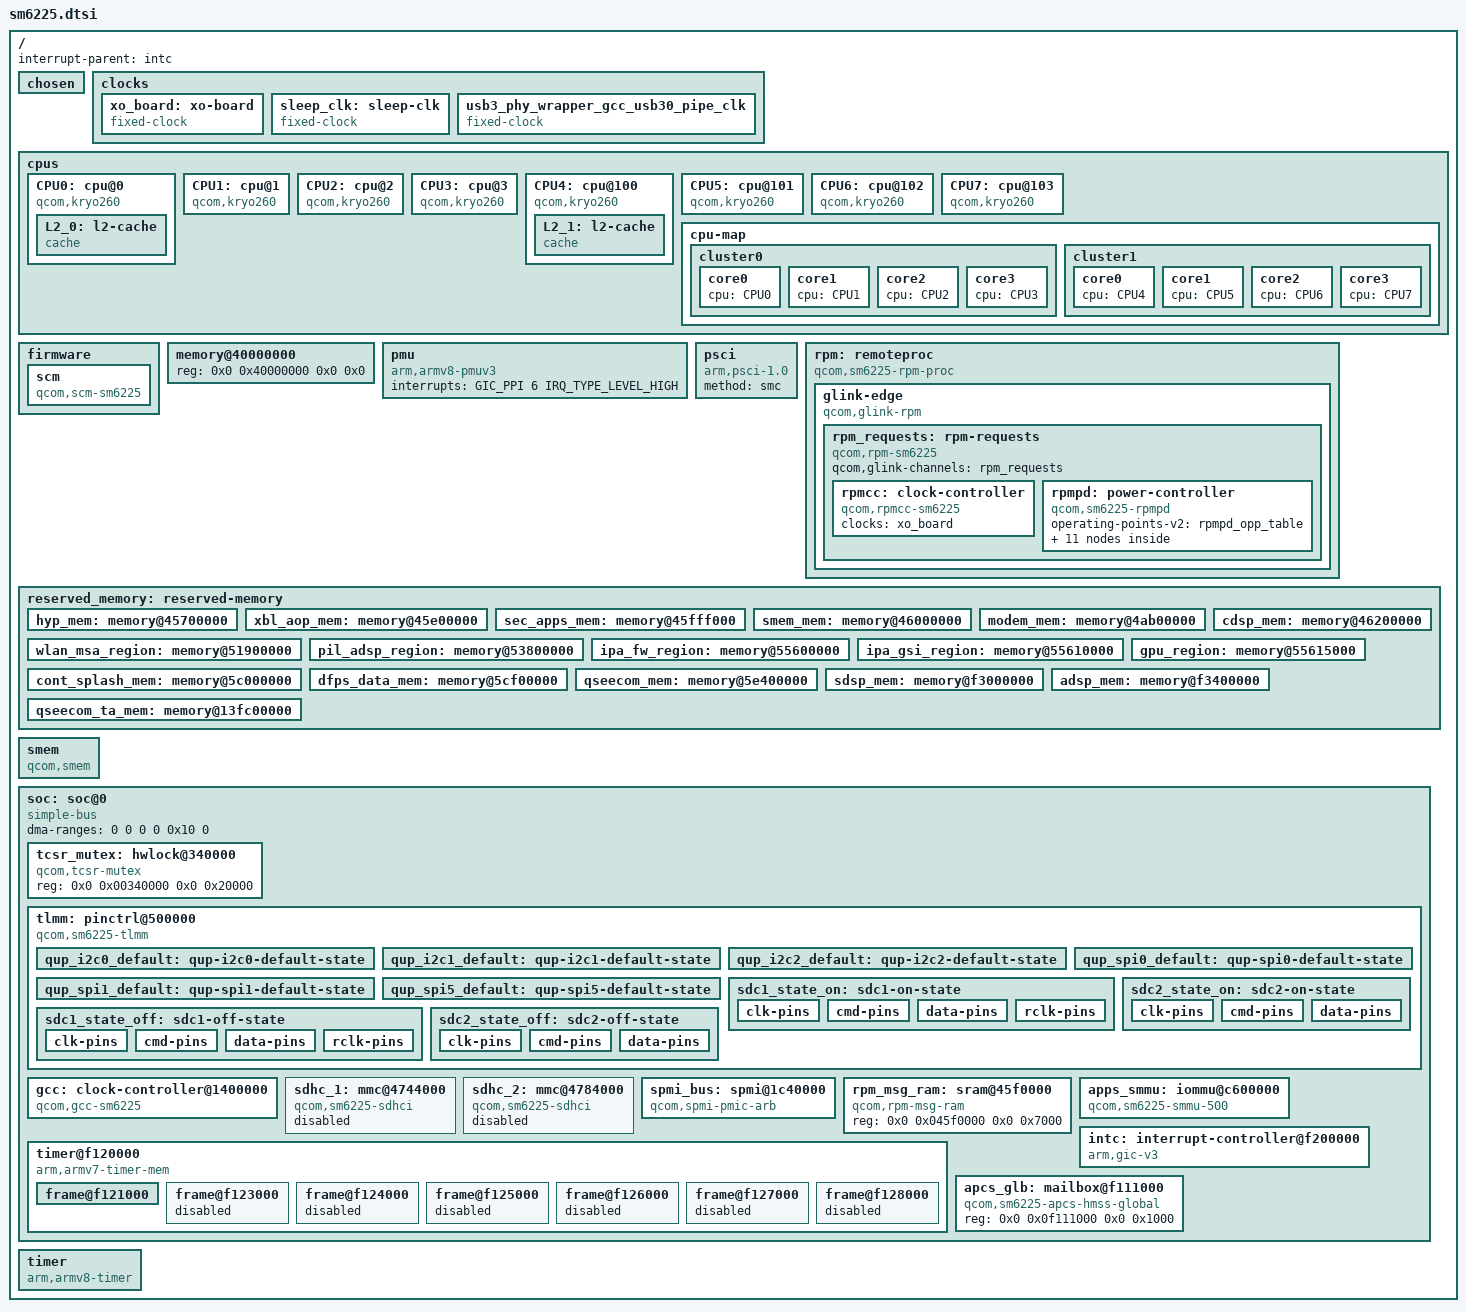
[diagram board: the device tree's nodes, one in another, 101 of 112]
// SPDX-License-Identifier: BSD-3-Clause
/*
 * Copyright (c) 2021, Martin Botka <martin.botka@somainline.org>
 */

#include <dt-bindings/clock/qcom,gcc-sm6225.h>
#include <dt-bindings/clock/qcom,rpmcc.h>
#include <dt-bindings/dma/qcom-gpi.h>
#include <dt-bindings/firmware/qcom,scm.h>
#include <dt-bindings/gpio/gpio.h>
#include <dt-bindings/interconnect/qcom,sm6115.h>
#include <dt-bindings/interconnect/qcom,rpm-icc.h>
#include <dt-bindings/interrupt-controller/arm-gic.h>
#include <dt-bindings/power/qcom-rpmpd.h>
#include <dt-bindings/thermal/thermal.h>

/ {
	interrupt-parent = <&intc>;
	#address-cells = <2>;
	#size-cells = <2>;

	chosen { };

	clocks {
		xo_board: xo-board {
			compatible = "fixed-clock";
			#clock-cells = <0>;
			clock-frequency = <19200000>;
			clock-output-names = "xo_board";
		};

		sleep_clk: sleep-clk {
			compatible = "fixed-clock";
			#clock-cells = <0>;
			clock-frequency = <32764>;
			clock-output-names = "sleep_clk";
		};

		usb3_phy_wrapper_gcc_usb30_pipe_clk: usb3_phy_wrapper_gcc_usb30_pipe_clk {
			compatible = "fixed-clock";
			#clock-cells = <0>;
			clock-frequency = <1000>;
			clock-output-names = "usb3_phy_wrapper_gcc_usb30_pipe_clk";
		};
	};

	cpus {
		#address-cells = <2>;
		#size-cells = <0>;

		CPU0: cpu@0 {
			device_type = "cpu";
			compatible = "qcom,kryo260";
			reg = <0x0 0x0>;
			enable-method = "psci";
			capacity-dmips-mhz = <1024>;
			next-level-cache = <&L2_0>;
			L2_0: l2-cache {
				compatible = "cache";
			};
		};

		CPU1: cpu@1 {
			device_type = "cpu";
			compatible = "qcom,kryo260";
			reg = <0x0 0x1>;
			enable-method = "psci";
			capacity-dmips-mhz = <1024>;
			next-level-cache = <&L2_0>;
		};

		CPU2: cpu@2 {
			device_type = "cpu";
			compatible = "qcom,kryo260";
			reg = <0x0 0x2>;
			enable-method = "psci";
			capacity-dmips-mhz = <1024>;
			next-level-cache = <&L2_0>;
		};

		CPU3: cpu@3 {
			device_type = "cpu";
			compatible = "qcom,kryo260";
			reg = <0x0 0x3>;
			enable-method = "psci";
			capacity-dmips-mhz = <1024>;
			next-level-cache = <&L2_0>;
		};

		CPU4: cpu@100 {
			device_type = "cpu";
			compatible = "qcom,kryo260";
			reg = <0x0 0x100>;
			enable-method = "psci";
			capacity-dmips-mhz = <1638>;
			next-level-cache = <&L2_1>;
			L2_1: l2-cache {
				compatible = "cache";
			};
		};

		CPU5: cpu@101 {
			device_type = "cpu";
			compatible = "qcom,kryo260";
			reg = <0x0 0x101>;
			enable-method = "psci";
			capacity-dmips-mhz = <1638>;
			next-level-cache = <&L2_1>;
		};

		CPU6: cpu@102 {
			device_type = "cpu";
			compatible = "qcom,kryo260";
			reg = <0x0 0x102>;
			enable-method = "psci";
			capacity-dmips-mhz = <1638>;
			next-level-cache = <&L2_1>;
		};

		CPU7: cpu@103 {
			device_type = "cpu";
			compatible = "qcom,kryo260";
			reg = <0x0 0x103>;
			enable-method = "psci";
			capacity-dmips-mhz = <1638>;
			next-level-cache = <&L2_1>;
		};

		cpu-map {
			cluster0 {
				core0 {
					cpu = <&CPU0>;
				};

				core1 {
					cpu = <&CPU1>;
				};

				core2 {
					cpu = <&CPU2>;
				};

				core3 {
					cpu = <&CPU3>;
				};
			};

			cluster1 {
				core0 {
					cpu = <&CPU4>;
				};

				core1 {
					cpu = <&CPU5>;
				};

				core2 {
					cpu = <&CPU6>;
				};

				core3 {
					cpu = <&CPU7>;
				};
			};
		};
	};

	firmware {
		scm: scm {
			compatible = "qcom,scm-sm6225", "qcom,scm";
			#reset-cells = <1>;
		};
	};

	memory@40000000 {
		/* We expect the bootloader to fill in the size */
		reg = <0x0 0x40000000 0x0 0x0>;
		device_type = "memory";
	};

	pmu {
		compatible = "arm,armv8-pmuv3";
		interrupts = <GIC_PPI 6 IRQ_TYPE_LEVEL_HIGH>;
	};

	psci {
		compatible = "arm,psci-1.0";
		method = "smc";
	};

	rpm: remoteproc {
		compatible = "qcom,sm6225-rpm-proc", "qcom,rpm-proc";

		glink-edge {
			compatible = "qcom,glink-rpm";

			interrupts = <GIC_SPI 194 IRQ_TYPE_EDGE_RISING>;
			qcom,rpm-msg-ram = <&rpm_msg_ram>;
			mboxes = <&apcs_glb 0>;

			rpm_requests: rpm-requests {
				compatible = "qcom,rpm-sm6225";
				qcom,glink-channels = "rpm_requests";

				rpmcc: clock-controller {
					compatible = "qcom,rpmcc-sm6225", "qcom,rpmcc";
					#clock-cells = <1>;
					clocks = <&xo_board>;
					clock-names = "xo";
				};

				rpmpd: power-controller {
					compatible = "qcom,sm6225-rpmpd";
					#power-domain-cells = <1>;
					operating-points-v2 = <&rpmpd_opp_table>;

					rpmpd_opp_table: opp-table {
						compatible = "operating-points-v2";

						rpmpd_opp_ret: opp1 {
							opp-level = <RPM_SMD_LEVEL_RETENTION>;
						};

						rpmpd_opp_ret_plus: opp2 {
							opp-level = <RPM_SMD_LEVEL_RETENTION_PLUS>;
						};

						rpmpd_opp_min_svs: opp3 {
							opp-level = <RPM_SMD_LEVEL_MIN_SVS>;
						};

						rpmpd_opp_low_svs: opp4 {
							opp-level = <RPM_SMD_LEVEL_LOW_SVS>;
						};

						rpmpd_opp_svs: opp5 {
							opp-level = <RPM_SMD_LEVEL_SVS>;
						};

						rpmpd_opp_svs_plus: opp6 {
							opp-level = <RPM_SMD_LEVEL_SVS_PLUS>;
						};

						rpmpd_opp_nom: opp7 {
							opp-level = <RPM_SMD_LEVEL_NOM>;
						};

						rpmpd_opp_nom_plus: opp8 {
							opp-level = <RPM_SMD_LEVEL_NOM_PLUS>;
						};

						rpmpd_opp_turbo: opp9 {
							opp-level = <RPM_SMD_LEVEL_TURBO>;
						};

						rpmpd_opp_turbo_no_cpr: opp10 {
							opp-level = <RPM_SMD_LEVEL_TURBO_NO_CPR>;
						};
					};
				};
			};
		};
	};

	reserved_memory: reserved-memory {
		#address-cells = <2>;
		#size-cells = <2>;
		ranges;

		hyp_mem: memory@45700000 {
			reg = <0x0 0x45700000 0x0 0x600000>;
			no-map;
		};

		xbl_aop_mem: memory@45e00000 {
			reg = <0x0 0x45e00000 0x0 0x140000>;
			no-map;
		};

		sec_apps_mem: memory@45fff000 {
			reg = <0x0 0x45fff000 0x0 0x1000>;
			no-map;
		};

		smem_mem: memory@46000000 {
			reg = <0x00 0x46000000 0x00 0x200000>;
			no-map;
		};

		modem_mem: memory@4ab00000 {
			reg = <0x00 0x4ab00000 0x00 0x6900000>;
			no-map;
		};

		wlan_msa_region: memory@51900000 {
			reg = <0x00 0x51900000 0x00 0x100000>;
			no-map;
		};

		cdsp_mem: memory@46200000 {
			reg = <0x00 0x46200000 0x00 0x1e00000>;
			no-map;
		};

		pil_adsp_region: memory@53800000 {
			reg = <0x00 0x53800000 0x00 0x1e00000>;
			no-map;
		};

		ipa_fw_region: memory@55600000 {
			reg = <0x00 0x55600000 0x00 0x10000>;
			no-map;
		};

		ipa_gsi_region: memory@55610000 {
			reg = <0x00 0x55610000 0x00 0x5000>;
			no-map;
		};

		gpu_region: memory@55615000 {
			reg = <0x00 0x55615000 0x00 0x2000>;
			no-map;
		};

		cont_splash_mem: memory@5c000000 {
			reg = <0x0 0x5c000000 0x0 0x00f00000>;
			no-map;
		};

		dfps_data_mem: memory@5cf00000 {
			reg = <0x0 0x5cf00000 0x0 0x0100000>;
			no-map;
		};

		qseecom_mem: memory@5e400000 {
			reg = <0x0 0x5e400000 0x0 0x1400000>;
			no-map;
		};

		sdsp_mem: memory@f3000000 {
			reg = <0x0 0xf3000000 0x0 0x400000>;
			no-map;
		};

		adsp_mem: memory@f3400000 {
			reg = <0x0 0xf3400000 0x0 0x800000>;
			no-map;
		};

		qseecom_ta_mem: memory@13fc00000 {
			reg = <0x1 0x3fc00000 0x0 0x400000>;
			no-map;
		};
	};

	smem: smem {
		compatible = "qcom,smem";
		memory-region = <&smem_mem>;
		hwlocks = <&tcsr_mutex 3>;
	};

	soc: soc@0 {
		compatible = "simple-bus";
		#address-cells = <2>;
		#size-cells = <2>;
		ranges = <0 0 0 0 0x10 0>;
		dma-ranges = <0 0 0 0 0x10 0>;

		tcsr_mutex: hwlock@340000 {
			compatible = "qcom,tcsr-mutex";
			reg = <0x0 0x00340000 0x0 0x20000>;
			#hwlock-cells = <1>;
		};

		tlmm: pinctrl@500000 {
			compatible = "qcom,sm6225-tlmm";
			reg = <0x0 0x00500000 0x0 0x400000>,
			      <0x0 0x00900000 0x0 0x400000>,
			      <0x0 0x00d00000 0x0 0x400000>;
			reg-names = "west", "south", "east";
			interrupts = <GIC_SPI 227 IRQ_TYPE_LEVEL_HIGH>;
			gpio-controller;
			gpio-ranges = <&tlmm 0 0 114>; /* GPIOs + ufs_reset */
			#gpio-cells = <2>;
			interrupt-controller;
			#interrupt-cells = <2>;

			qup_i2c0_default: qup-i2c0-default-state {
				pins = "gpio0", "gpio1";
				function = "qup0";
				drive-strength = <2>;
				bias-pull-up;
			};

			qup_i2c1_default: qup-i2c1-default-state {
				pins = "gpio4", "gpio5";
				function = "qup1";
				drive-strength = <2>;
				bias-pull-up;
			};

			qup_i2c2_default: qup-i2c2-default-state {
				pins = "gpio6", "gpio7";
				function = "qup2";
				drive-strength = <2>;
				bias-pull-up;
			};

			qup_spi0_default: qup-spi0-default-state {
				pins = "gpio0", "gpio1","gpio2", "gpio3";
				function = "qup0";
				drive-strength = <2>;
				bias-pull-up;
			};

			qup_spi1_default: qup-spi1-default-state {
				pins = "gpio4", "gpio5", "gpio69", "gpio70";
				function = "qup1";
				drive-strength = <2>;
				bias-pull-up;
			};

			qup_spi5_default: qup-spi5-default-state {
				pins = "gpio14", "gpio15", "gpio16", "gpio17";
				function = "qup5";
				drive-strength = <2>;
				bias-pull-up;
			};

			sdc1_state_on: sdc1-on-state {
				clk-pins {
					pins = "sdc1_clk";
					bias-disable;
					drive-strength = <16>;
				};

				cmd-pins {
					pins = "sdc1_cmd";
					bias-pull-up;
					drive-strength = <10>;
				};

				data-pins {
					pins = "sdc1_data";
					bias-pull-up;
					drive-strength = <10>;
				};

				rclk-pins {
					pins = "sdc1_rclk";
					bias-pull-down;
				};
			};

			sdc1_state_off: sdc1-off-state {
				clk-pins {
					pins = "sdc1_clk";
					bias-disable;
					drive-strength = <2>;
				};

				cmd-pins {
					pins = "sdc1_cmd";
					bias-pull-up;
					drive-strength = <2>;
				};

				data-pins {
					pins = "sdc1_data";
					bias-pull-up;
					drive-strength = <2>;
				};

				rclk-pins {
					pins = "sdc1_rclk";
					bias-pull-down;
				};
			};

			sdc2_state_on: sdc2-on-state {
				clk-pins {
					pins = "sdc2_clk";
					bias-disable;
					drive-strength = <16>;
				};

				cmd-pins {
					pins = "sdc2_cmd";
					bias-pull-up;
					drive-strength = <10>;
				};

				data-pins {
					pins = "sdc2_data";
					bias-pull-up;
					drive-strength = <10>;
				};
			};

			sdc2_state_off: sdc2-off-state {
				clk-pins {
					pins = "sdc2_clk";
					bias-disable;
					drive-strength = <2>;
				};

				cmd-pins {
					pins = "sdc2_cmd";
					bias-pull-up;
					drive-strength = <2>;
				};

				data-pins {
					pins = "sdc2_data";
					bias-pull-up;
					drive-strength = <2>;
				};
			};
		};

		gcc: clock-controller@1400000 {
			compatible = "qcom,gcc-sm6225";
			reg = <0x0 0x01400000 0x0 0x1f0000>;
			clocks = <&rpmcc RPM_SMD_XO_CLK_SRC>, <&sleep_clk>;
			clock-names = "bi_tcxo", "sleep_clk";
			#clock-cells = <1>;
			#reset-cells = <1>;
			#power-domain-cells = <1>;
		};

		sdhc_1: mmc@4744000 {
			compatible = "qcom,sm6225-sdhci", "qcom,sdhci-msm-v5";
			reg = <0x0 0x04744000 0x0 0x1000>, <0x0 0x04745000 0x0 0x1000>;
			reg-names = "hc", "cqhci";

			interrupts = <GIC_SPI 348 IRQ_TYPE_LEVEL_HIGH>,
				     <GIC_SPI 352 IRQ_TYPE_LEVEL_HIGH>;
			interrupt-names = "hc_irq", "pwr_irq";

			clocks = <&gcc GCC_SDCC1_AHB_CLK>,
				 <&gcc GCC_SDCC1_APPS_CLK>,
				 <&rpmcc RPM_SMD_XO_CLK_SRC>;
			clock-names = "iface", "core", "xo";
			iommus = <&apps_smmu 0x160 0x0>;

			power-domains = <&rpmpd SM6225_VDDCX>;

			qcom,dll-config = <0x000f642c>;
			qcom,ddr-config = <0x80040873>;

			bus-width = <8>;
			non-removable;
			supports-cqe;

			status = "disabled";
		};

		sdhc_2: mmc@4784000 {
			compatible = "qcom,sm6225-sdhci", "qcom,sdhci-msm-v5";
			reg = <0x0 0x04784000 0x0 0x1000>;
			reg-names = "hc";

			interrupts = <GIC_SPI 350 IRQ_TYPE_LEVEL_HIGH>,
				     <GIC_SPI 353 IRQ_TYPE_LEVEL_HIGH>;
			interrupt-names = "hc_irq", "pwr_irq";

			clocks = <&gcc GCC_SDCC2_AHB_CLK>,
				 <&gcc GCC_SDCC2_APPS_CLK>,
				 <&rpmcc RPM_SMD_XO_CLK_SRC>;
			clock-names = "iface", "core", "xo";
			iommus = <&apps_smmu 0x180 0x0>;

			pinctrl-0 = <&sdc2_state_on>;
			pinctrl-1 = <&sdc2_state_off>;
			pinctrl-names = "default", "sleep";

			power-domains = <&rpmpd SM6225_VDDCX>;

			qcom,dll-config = <0x0007642c>;
			qcom,ddr-config = <0x80040873>;

			bus-width = <4>;
			status = "disabled";
		};


		spmi_bus: spmi@1c40000 {
			compatible = "qcom,spmi-pmic-arb";
			reg = <0x0 0x01c40000 0x0 0x1100>,
			      <0x0 0x01e00000 0x0 0x2000000>,
			      <0x0 0x03e00000 0x0 0x100000>,
			      <0x0 0x03f00000 0x0 0xa0000>,
			      <0x0 0x01c0a000 0x0 0x26000>;
			reg-names = "core", "chnls", "obsrvr", "intr", "cnfg";
			interrupt-names = "periph_irq";
			interrupts = <GIC_SPI 183 IRQ_TYPE_LEVEL_HIGH>;
			qcom,ee = <0>;
			qcom,channel = <0>;
			#address-cells = <2>;
			#size-cells = <0>;
			interrupt-controller;
			#interrupt-cells = <4>;
		};

		rpm_msg_ram: sram@45f0000 {
			compatible = "qcom,rpm-msg-ram";
			reg = <0x0 0x045f0000 0x0 0x7000>;
		};

		timer@f120000 {
			compatible = "arm,armv7-timer-mem";
			reg = <0x0 0x0f120000 0x0 0x1000>;
			#address-cells = <2>;
			#size-cells = <1>;
			ranges = <0x0 0x0 0x0 0x0 0x20000000>;
			clock-frequency = <19200000>;

			frame@f121000 {
				reg = <0x0 0x0f121000 0x1000>, <0x0 0x0f122000 0x1000>;
				frame-number = <0>;
				interrupts = <GIC_SPI 8 IRQ_TYPE_LEVEL_HIGH>,
					     <GIC_SPI 7 IRQ_TYPE_LEVEL_HIGH>;
			};

			frame@f123000 {
				reg = <0x0 0x0f123000 0x1000>;
				frame-number = <1>;
				interrupts = <GIC_SPI 9 IRQ_TYPE_LEVEL_HIGH>;
				status = "disabled";
			};

			frame@f124000 {
				reg = <0x0 0x0f124000 0x1000>;
				frame-number = <2>;
				interrupts = <GIC_SPI 10 IRQ_TYPE_LEVEL_HIGH>;
				status = "disabled";
			};

			frame@f125000 {
				reg = <0x0 0x0f125000 0x1000>;
				frame-number = <3>;
				interrupts = <GIC_SPI 11 IRQ_TYPE_LEVEL_HIGH>;
				status = "disabled";
			};

			frame@f126000 {
				reg = <0x0 0x0f126000 0x1000>;
				frame-number = <4>;
				interrupts = <GIC_SPI 12 IRQ_TYPE_LEVEL_HIGH>;
				status = "disabled";
			};

			frame@f127000 {
				reg = <0x0 0x0f127000 0x1000>;
				frame-number = <5>;
				interrupts = <GIC_SPI 13 IRQ_TYPE_LEVEL_HIGH>;
				status = "disabled";
			};

			frame@f128000 {
				reg = <0x0 0x0f128000 0x1000>;
				frame-number = <6>;
				interrupts = <GIC_SPI 14 IRQ_TYPE_LEVEL_HIGH>;
				status = "disabled";
			};
		};

		apps_smmu: iommu@c600000 {
			compatible = "qcom,sm6225-smmu-500", "qcom,smmu-500", "arm,mmu-500";
			reg = <0x0 0x0c600000 0x0 0x80000>;
			#iommu-cells = <2>;
			#global-interrupts = <1>;

			interrupts = <GIC_SPI 81 IRQ_TYPE_LEVEL_HIGH>,
				     <GIC_SPI 88 IRQ_TYPE_LEVEL_HIGH>,
				     <GIC_SPI 89 IRQ_TYPE_LEVEL_HIGH>,
				     <GIC_SPI 90 IRQ_TYPE_LEVEL_HIGH>,
				     <GIC_SPI 91 IRQ_TYPE_LEVEL_HIGH>,
				     <GIC_SPI 92 IRQ_TYPE_LEVEL_HIGH>,
				     <GIC_SPI 93 IRQ_TYPE_LEVEL_HIGH>,
				     <GIC_SPI 94 IRQ_TYPE_LEVEL_HIGH>,
				     <GIC_SPI 95 IRQ_TYPE_LEVEL_HIGH>,
				     <GIC_SPI 96 IRQ_TYPE_LEVEL_HIGH>,
				     <GIC_SPI 97 IRQ_TYPE_LEVEL_HIGH>,
				     <GIC_SPI 98 IRQ_TYPE_LEVEL_HIGH>,
				     <GIC_SPI 99 IRQ_TYPE_LEVEL_HIGH>,
				     <GIC_SPI 100 IRQ_TYPE_LEVEL_HIGH>,
				     <GIC_SPI 101 IRQ_TYPE_LEVEL_HIGH>,
				     <GIC_SPI 102 IRQ_TYPE_LEVEL_HIGH>,
				     <GIC_SPI 103 IRQ_TYPE_LEVEL_HIGH>,
				     <GIC_SPI 104 IRQ_TYPE_LEVEL_HIGH>,
				     <GIC_SPI 105 IRQ_TYPE_LEVEL_HIGH>,
				     <GIC_SPI 106 IRQ_TYPE_LEVEL_HIGH>,
				     <GIC_SPI 107 IRQ_TYPE_LEVEL_HIGH>,
				     <GIC_SPI 108 IRQ_TYPE_LEVEL_HIGH>,
				     <GIC_SPI 109 IRQ_TYPE_LEVEL_HIGH>,
				     <GIC_SPI 110 IRQ_TYPE_LEVEL_HIGH>,
				     <GIC_SPI 111 IRQ_TYPE_LEVEL_HIGH>,
				     <GIC_SPI 112 IRQ_TYPE_LEVEL_HIGH>,
				     <GIC_SPI 113 IRQ_TYPE_LEVEL_HIGH>,
				     <GIC_SPI 114 IRQ_TYPE_LEVEL_HIGH>,
				     <GIC_SPI 115 IRQ_TYPE_LEVEL_HIGH>,
				     <GIC_SPI 116 IRQ_TYPE_LEVEL_HIGH>,
				     <GIC_SPI 117 IRQ_TYPE_LEVEL_HIGH>,
				     <GIC_SPI 118 IRQ_TYPE_LEVEL_HIGH>,
				     <GIC_SPI 119 IRQ_TYPE_LEVEL_HIGH>,
				     <GIC_SPI 120 IRQ_TYPE_LEVEL_HIGH>,
				     <GIC_SPI 121 IRQ_TYPE_LEVEL_HIGH>,
				     <GIC_SPI 122 IRQ_TYPE_LEVEL_HIGH>,
				     <GIC_SPI 123 IRQ_TYPE_LEVEL_HIGH>,
				     <GIC_SPI 124 IRQ_TYPE_LEVEL_HIGH>,
				     <GIC_SPI 125 IRQ_TYPE_LEVEL_HIGH>,
				     <GIC_SPI 126 IRQ_TYPE_LEVEL_HIGH>,
				     <GIC_SPI 127 IRQ_TYPE_LEVEL_HIGH>,
				     <GIC_SPI 128 IRQ_TYPE_LEVEL_HIGH>,
				     <GIC_SPI 129 IRQ_TYPE_LEVEL_HIGH>,
				     <GIC_SPI 130 IRQ_TYPE_LEVEL_HIGH>,
				     <GIC_SPI 131 IRQ_TYPE_LEVEL_HIGH>,
				     <GIC_SPI 132 IRQ_TYPE_LEVEL_HIGH>,
				     <GIC_SPI 133 IRQ_TYPE_LEVEL_HIGH>,
				     <GIC_SPI 134 IRQ_TYPE_LEVEL_HIGH>,
				     <GIC_SPI 135 IRQ_TYPE_LEVEL_HIGH>,
				     <GIC_SPI 136 IRQ_TYPE_LEVEL_HIGH>,
				     <GIC_SPI 137 IRQ_TYPE_LEVEL_HIGH>,
				     <GIC_SPI 138 IRQ_TYPE_LEVEL_HIGH>,
				     <GIC_SPI 139 IRQ_TYPE_LEVEL_HIGH>,
				     <GIC_SPI 140 IRQ_TYPE_LEVEL_HIGH>,
				     <GIC_SPI 141 IRQ_TYPE_LEVEL_HIGH>,
				     <GIC_SPI 142 IRQ_TYPE_LEVEL_HIGH>,
				     <GIC_SPI 143 IRQ_TYPE_LEVEL_HIGH>,
				     <GIC_SPI 144 IRQ_TYPE_LEVEL_HIGH>,
				     <GIC_SPI 145 IRQ_TYPE_LEVEL_HIGH>,
				     <GIC_SPI 146 IRQ_TYPE_LEVEL_HIGH>,
				     <GIC_SPI 147 IRQ_TYPE_LEVEL_HIGH>,
				     <GIC_SPI 148 IRQ_TYPE_LEVEL_HIGH>,
				     <GIC_SPI 149 IRQ_TYPE_LEVEL_HIGH>,
				     <GIC_SPI 150 IRQ_TYPE_LEVEL_HIGH>,
				     <GIC_SPI 151 IRQ_TYPE_LEVEL_HIGH>;
		};

		intc: interrupt-controller@f200000 {
			compatible = "arm,gic-v3";
			reg = <0x0 0x0f200000 0x0 0x10000>,
			      <0x0 0x0f300000 0x0 0x100000>;
			#interrupt-cells = <3>;
			interrupt-controller;
			interrupt-parent = <&intc>;
			#redistributor-regions = <1>;
			redistributor-stride = <0x0 0x20000>;
			interrupts = <GIC_PPI 9 IRQ_TYPE_LEVEL_HIGH>;
		};

		apcs_glb: mailbox@f111000 {
			compatible = "qcom,sm6225-apcs-hmss-global",
				     "qcom,msm8994-apcs-kpss-global";
			reg = <0x0 0x0f111000 0x0 0x1000>;

			#mbox-cells = <1>;
		};
	};

	timer {
		compatible = "arm,armv8-timer";
		interrupts = <GIC_PPI 1 (GIC_CPU_MASK_SIMPLE(4) | IRQ_TYPE_LEVEL_LOW)>,
			     <GIC_PPI 2 (GIC_CPU_MASK_SIMPLE(4) | IRQ_TYPE_LEVEL_LOW)>,
			     <GIC_PPI 3 (GIC_CPU_MASK_SIMPLE(4) | IRQ_TYPE_LEVEL_LOW)>,
			     <GIC_PPI 0 (GIC_CPU_MASK_SIMPLE(4) | IRQ_TYPE_LEVEL_LOW)>;
	};
};
